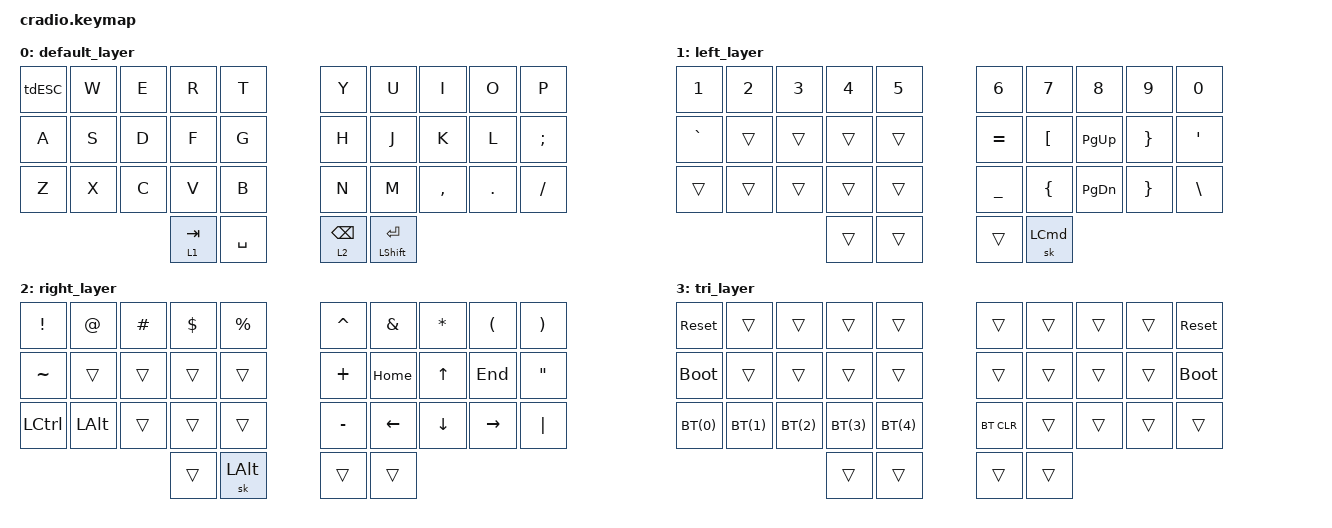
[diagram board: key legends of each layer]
// Copyright (c) 2022 The ZMK Contributors
// SPDX-License-Identifier: MIT

#include <behaviors.dtsi>
#include <dt-bindings/zmk/keys.h>
#include <dt-bindings/zmk/bt.h>

// Home row mods macro
#define BT(n) &bt BT_SEL n

/ {
    behaviors {
        tdESC: tap_ESC {
            compatible = "zmk,behavior-tap-dance";
            #binding-cells = <0>;
            tapping-term-ms = <200>;
            bindings = <&kp Q>, <&kp ESC>;
        };
    };

    conditional_layers {
        compatible = "zmk,conditional-layers";
        tri_layer {
            if-layers = <1 2>;
            then-layer = <3>;
        };
    };

    keymap {
        compatible = "zmk,keymap";
        default_layer {
            bindings = <
        //╭──────────┬──────────┬──────────┬──────────┬──────────╮   ╭──────────┬──────────┬──────────┬──────────┬──────────╮
        //│  Q       │  W       │  E       │  R       │  T       │   │  Y       │  U       │  I       │  O       │  P       │
            &tdESC     &kp W      &kp E      &kp R      &kp T          &kp Y      &kp U      &kp I      &kp O      &kp P
        //├──────────┼──────────┼──────────┼──────────┼──────────┤   ├──────────┼──────────┼──────────┼──────────┼──────────┤
        //│  A       │  S       │  D       │  F       │  G       │   │  H       │  J       │  K       │  L       │ : ;      │
            &kp A      &kp S      &kp D      &kp F      &kp G          &kp H      &kp J      &kp K      &kp L      &kp SEMI
        //├──────────┼──────────┼──────────┼──────────┼──────────┤   ├──────────┼──────────┼──────────┼──────────┼──────────┤
        //│  Z       │  X       │  C       │  V       │  B       │   │  N       │  M       │ , <      │ . >      │ ? /      │
            &kp Z      &kp X      &kp C      &kp V      &kp B          &kp N      &kp M     &kp COMMA   &kp DOT    &kp FSLH
        //╰──────────┴──────────┴──────────┼──────────┼──────────┤   ├──────────┼──────────┼──────────┴──────────┴──────────╯
                                         &lt 1 TAB   &kp SPACE        &lt 2 BSPC  &mt LSHIFT ENTER
        //                                 ╰──────────┴──────────╯   ╰──────────┴──────────╯
            >;
        };

        left_layer {
            bindings = <
        //╭──────────┬──────────┬──────────┬──────────┬──────────╮   ╭──────────┬──────────┬──────────┬──────────┬──────────╮
        //│  1       │  2       │  3       │  4       │  5       │   │ 6        │ 7        │ 8        │  9       │  0       │
            &kp N1     &kp N2     &kp N3     &kp N4     &kp N5         &kp N6     &kp N7     &kp N8     &kp N9     &kp N0
        //├──────────┼──────────┼──────────┼──────────┼──────────┤   ├──────────┼──────────┼──────────┼──────────┼──────────┤
        //│  `       │          │          │          │          │   │ =        │ [        │  PgUp    │  ]       │  '       |                                                                                                    "
            &kp GRAVE  &trans     &trans     &trans     &trans        &kp EQUAL   &kp LBKT   &kp PG_UP   &kp RBRC   &kp SQT
        //├──────────┼──────────┼──────────┼──────────┼──────────┤   ├──────────┼──────────┼──────────┼──────────┼──────────┤
        //│  Ctrl    │  Alt     │          │          │          │   │ _        │ {        │  PdDn    │  }       │   \      │
            &trans     &trans     &trans     &trans     &trans        &kp UNDER   &kp LBRC  &kp PG_DN   &kp RBRC    &kp BSLH
        //╰──────────┴──────────┴──────────┼──────────┼──────────┤   ├──────────┼──────────┼──────────┴──────────┴──────────╯
                                              &trans     &trans         &trans    &sk LCMD 
        //                                 ╰──────────┴──────────╯   ╰──────────┴──────────╯
            >;
        };

        right_layer {
            bindings = <
        //╭──────────┬──────────┬──────────┬──────────┬──────────╮   ╭──────────┬──────────┬──────────┬──────────┬──────────╮
        //│  !       │  @       │  #       │  $       │  %       │   │  ^       │  &       │  *       │  (       │  )       │
            &kp EXCL   &kp AT     &kp HASH   &kp DLLR   &kp PRCNT      &kp CARET  &kp AMPS   &kp ASTRK  &kp LPAR   &kp RPAR
        //├──────────┼──────────┼──────────┼──────────┼──────────┤   ├──────────┼──────────┼──────────┼──────────┼──────────┤
        //│  ~       │          │          │          │          │   │  +       │ Home     │ UP       │ End      │   "      │
           &kp TILDE    &trans     &trans     &trans     &trans        &kp PLUS   &kp HOME   &kp UP     &kp END   &kp DQT
        //├──────────┼──────────┼──────────┼──────────┼──────────┤   ├──────────┼──────────┼──────────┼──────────┼──────────┤
        //│  Ctrl    │  Alt     │          │          │          │   │  -       │  LEFT    │ DOWN     │ RIGHT    │  |       │
            &kp LCTRL  &kp LALT     &trans     &trans     &trans       &kp MINUS  &kp LEFT   &kp DOWN  &kp RIGHT   &kp PIPE
        //╰──────────┴──────────┴──────────┼──────────┼──────────┤   ├──────────┼──────────┼──────────┴──────────┴──────────╯
                                              &trans    &sk LALT        &trans     &trans
        //                                 ╰──────────┴──────────╯   ╰──────────┴──────────╯
            >;
        };

        tri_layer {
            bindings = <
        //╭──────────┬──────────┬──────────┬──────────┬──────────╮   ╭──────────┬──────────┬──────────┬──────────┬──────────╮
        //│ Q - RST  │  W       │  E       │  R       │  T       │   │  Y       │  U       │  I       │  O       │  P - RST │
           &sys_reset  &trans     &trans     &trans     &trans         &trans     &trans     &trans     &trans    &sys_reset
        //├──────────┼──────────┼──────────┼──────────┼──────────┤   ├──────────┼──────────┼──────────┼──────────┼──────────┤
        //│ A - BOOT │  S       │  D       │  F       │  G       │   │  H       │  J       │  K       │  L       │ ; - BOOT │
          &bootloader  &trans     &trans     &trans    &trans          &trans     &trans     &trans     &trans    &bootloader
        //├──────────┼──────────┼──────────┼──────────┼──────────┤   ├──────────┼──────────┼──────────┼──────────┼──────────┤
        //│  Z       │  X       │  C       │  V       │  B       │   │ N - BTCLR│  M       │ , <      │ . >      │ / ?      │
            BT(0)      BT(1)      BT(2)      BT(3)      BT(4)         &bt BT_CLR  &trans     &trans     &trans     &trans
        //╰──────────┴──────────┴──────────┼──────────┼──────────┤   ├──────────┼──────────┼──────────┴──────────┴──────────╯
                                             &trans     &trans         &trans     &trans
        //                                 ╰──────────┴──────────╯   ╰──────────┴──────────╯
            >;
        };
    };
};
